# NUC400_v1 register map
File version: 1.0
Registers are 32-bit, read-write, reset 0x0 unless marked. A register's access mark holds for its fields unless they carry their own. Offsets are from the block's base; [hi:lo] are bit positions.

## OTG — OTG Register Map
Base 0x4004D000
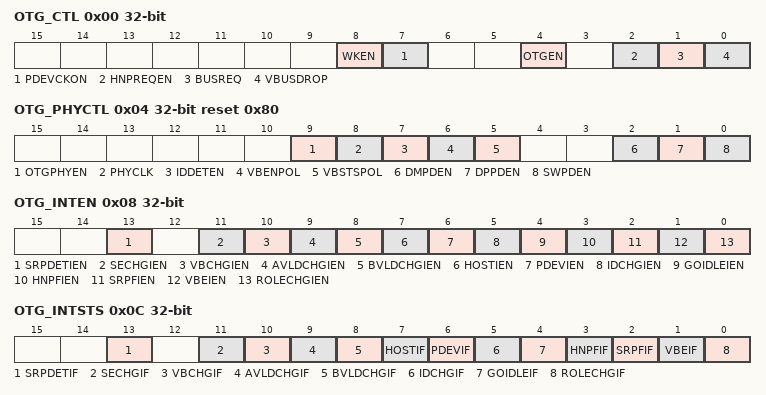
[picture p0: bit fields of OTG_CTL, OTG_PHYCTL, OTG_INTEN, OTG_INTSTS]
0x00 OTG_CTL — OTG Control Register
  [8] WKEN — OTG Wake-Up Enable Bit
    0=OTG ID pin status change wake-up Disabled; 1=OTG ID pin status change wake-up Enabled
  [7] PDEVCKON — Force OTG PHY Output Clock To USB Device. If software configures OTG controller as OTG device and OTG device as A-device, OTG controller will output OTG PHY clock (30 MHz) to USB device only when OTG device as A-peripheral. If software needs to configure USB device before role change (from A-Host to A-Peripheral), software can set this bit high to output OTG PHY clock to USB device.
    0=USB device clock is available only when OTG device as a peripheral; 1=Force output OTG PHY clock to USB device
  [4] OTGEN — OTG Function Enable Bit. If USB is configured as OTG device, this bit must set high.
    0=OTG function Disabled; 1=OTG function Enabled
  [2] HNPREQEN — OTG B-Device HNP Enable/Request. Set this bit to TRUE after the OTG A-device successfully sends a SetFeature(b_hnp_enable) command to the OTG B-device This bit will be cleared automatically when a bus reset or SESS_VLD goes from TRUE to FALSE.
  [1] BUSREQ — OTG A-Device Bus Request. If user application of an OTG A-device wants to do data transfers via USB bus, set this bit to high Otherwise if user application won't use the bus any more, set this bit low. This bit will be automatically cleared if VBUSDROP bit is set to TRUE.
  [0] VBUSDROP — Drop The VUSB Bus. If user application running on this OTG A-device wants to conserve power consumption, set this bit to high When set this bit to TRUE, BUSREQ shall be cleared as well.
    0=Did Not drop the VBUS and keep going on USB data transfers; 1=Drop the VBUS to conserve power consumption
0x04 OTG_PHYCTL reset 0x80 — OTG PHY Control Register
  [9] OTGPHYEN — OTG PHY Enable Control when Device Configured as OTG-Device. When device is configured as OTG-device, hardware will not enable OTG PHY automatically. Software can set OTG_EN to enable OTG PHY.
    0=OTG PHY Disabled; 1=OTG PHY Enabled
  [8] PHYCLK — PHY Input Clock Selection
    0=PHY input clock is12 MHz; 1=PHY input clock is 24 MHz
  [7] IDDETEN — ID Detection Enable
    0=Sampling on ID pin Enabled; 1=Sampling on ID pin Disabled
  [6] VBENPOL — Off-Chip USB VBUS Power Enable Polarity. The OTG controller will enable off-chip USB VBUS LDO to provide VBUS power when need. The polarity of enabling off-chip BSU VBUS LDO (high active or low active) depends on the selected component. This bit provides the inverse option of off-chip USB VBUS LDO enable.
    0=The polarity of enabling off-chip USB VBUS LDO from the OTG controller not inversed; 1=The polarity of enabling off-chip USB VBUS LDO from the OTG controller inversed
  [5] VBSTSPOL — Off-Chip USB VBUS Power Status Polarity. The polarity of off-chip USB VBUS LDO valid depends on the selected component. This bit provides the inversed option of off-chip USB VBUS LDO valid.
    0=The polarity of off-chip USB VBUS LDO valid not inversed; 1=The polarity of off-chip USB VBUS LDO valid inversed
  [2] DMPDEN
    1=15 k resistor pull-down on D- pin Enabled
  [1] DPPDEN
    1=15 k resistor pull-down on D+ pin Enabled
  [0] SWPDEN — Software Control Pull-Down On Data Lines Enable Bit. Note: Software must set this bit high before controlling DPPDEN and DMPDEN.
    0=Pull-down resistors on data lines is controlled by OTG control logic; 1=Pull-down resistors on data lines is controlled by software
0x08 OTG_INTEN — OTG Interrupt Enable Register
  [13] SRPDETIEN — SRP Detected Interrupt Enable Bit
    0=Interrupt Disabled; 1=Interrupt Enabled
  [11] SECHGIEN — SESSEND Status Changed Interrupt Enable Bit
    0=Interrupt Disabled; 1=Interrupt Enabled
  [10] VBCHGIEN — VBVALID Status Changed Interrupt Enable Bit
    0=Interrupt Disabled; 1=Interrupt Enabled
  [9] AVLDCHGIEN — A-Device Session Valid Status Change (From High To Low Or From Low To High) Interrupt Enable Bit
    0=Interrupt Disabled; 1=Interrupt Enabled
  [8] BVLDCHGIEN — B-Device Session Valid Status Change (From High To Low Or From Low To High) Interrupt Enable Bit
    0=Interrupt Disabled; 1=Interrupt Enabled
  [7] HOSTIEN — Act As Host Interrupt Enable Bit
    0=This device as a host interrupt Disabled; 1=This device as a host interrupt Enabled
  [6] PDEVIEN — Act As Peripheral Interrupt Enable Bit
    0=This device as a peripheral interrupt Disabled; 1=This device as a peripheral interrupt Enabled
  [5] IDCHGIEN — IDSTS Changed Interrupt Enable
    0=Interrupt Disabled; 1=Interrupt Enabled
  [4] GOIDLEIEN — OTG Device Goes IDLE State Interrupt Enable Bit. Note: Going to idle state means going to a_idle or b_idle state. Please refer to A-device state diagram and B-device state diagram in OTG spec.
    0=Interrupt Disabled; 1=Interrupt Enabled
  [3] HNPFIEN — HNP Fail Interrupt Enable Bit
    0=Interrupt Disabled; 1=Interrupt Enabled
  [2] SRPFIEN — SRP Fail Interrupt Enable Bit
    0=Interrupt Disabled; 1=Interrupt Enabled
  [1] VBEIEN — VBUS Error Interrupt Enable Bit. Note: VBUS error means going to a_vbus_err state. Please refer to A-device state diagram in OTG spec.
    0=Interrupt Disabled; 1=Interrupt Enabled
  [0] ROLECHGIEN — Role(Host Or Peripheral) Changed Interrupt Enable Bit
    0=Interrupt Disabled; 1=Interrupt Enabled
0x0C OTG_INTSTS — OTG Interrupt Status Register
  [13] SRPDETIF — SRP Detected Interrupt Status. Note: Write 1 to clear this status.
    0=SRP not detected; 1=SRP detected
  [11] SECHGIF — SESSEND State Change Interrupt Status. Note: Write 1 to clear this flag.
    0=Session end not toggled; 1=SESSEND from high to low or from low to high
  [10] VBCHGIF — VBVALID State Change Interrupt Status. Note: Write 1 to clear this flag.
    0=VBUS_VLD not toggled; 1=VBUS_VLD from high to low or from low to high
  [9] AVLDCHGIF — A-Device Session Valid State Change Interrupt Status. Note: Write 1 to clear this flag.
    0=AVLD not toggled; 1=AVLD from high to low or low to high
  [8] BVLDCHGIF — B-Device Session Valid State Change Interrupt Status. Note: Write 1 to clear this status.
    0=BVLD not toggled; 1=BVLD from high to low or low to high
  [7] HOSTIF — Act As Host Interrupt Status. Note: Write 1 to clear this flag.
    0=This device does not act as a host; 1=This device acts as a host
  [6] PDEVIF — Act As Peripheral Interrupt Status. Note: Write 1 to clear this flag.
    0=This device does not act as a peripheral; 1=This device acts as a peripheral
  [5] IDCHGIF — ID State Change Interrupt Status. Note1: BUSREQ (OTG_CTL[1]) will be cleared when IDDIG is high. Note2: Write 1 to clear this flag.
    0=IDSTS not toggled; 1=IDSTS from high to low or from low to high
  [4] GOIDLEIF — OTG Device Goes IDLE Interrupt Status. Flag is set if the OTG device transfers from non-idle state to idle state. The OTG device will be neither a host nor a peripheral. Note: Write 1 to clear this flag.
    0=OTG device does not go back to idle state(a_idle or b_idle); 1=OTG device go back to idle state(a_idle or b_idle)
  [3] HNPFIF — HNP Fail Interrupt Status. When A-device has granted B-device to be host and USB bus in SE0 state, this bit will be set in specified interval (b_ase0_brst_tmr, defined in OTG spec. specification), A-device does not signal connect signal. Note: Write 1 to clear this flag.
  [2] SRPFIF — SRP Fail Interrupt Status. After initiating SRP, an OTG B-device will wait at least TB_SRP_FAIL min, defined in OTG specification, for the OTG A-device respond This flag is set when the OTG B-device didn't get the response from the remote A-device to turn VBUS on and generate a bus reset. Note: Write 1 to clear this flag.
  [1] VBEIF — VBUS Error Interrupt Status. This flag will be set in one of two conditions. One case is that voltage on VBUS cannot reach a minimum valid threshold 4.4V within a maximum time of 100ms after OTG A device starting to drive. The other case is that the supplied VBUS drops below a minimum valid threshold due to the overcurrent condition. Note: Write 1 to clear this flag and recover from the VBUS error state.
  [0] ROLECHGIF — OTG Role Change Interrupt Status. This flag is set when the role of an OTG device changed from a host to a peripheral, or changed from a peripheral to a host. Note: Write 1 to clear this flag.
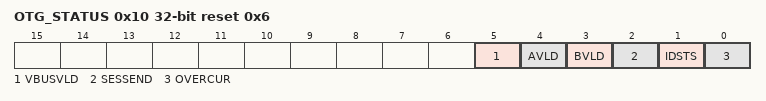
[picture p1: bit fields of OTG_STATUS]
0x10 OTG_STATUS ro reset 0x6 — Functional Status Register
  [5] VBUSVLD — VBUS Valid Status
    0=VBUS 4.4V; 1=VBUS 4.75V
  [4] AVLD — A-Device Session Valid Status
    0=VBUS 0.8V; 1=VBUS 2V
  [3] BVLD — B-Device Session Valid Status
    0=VBUS 0.8V; 1=VBUS 4V
  [2] SESSEND — Session End Status
    0=VBUS 0.8V; 1=VBUS 0.2V
  [1] IDSTS — ID Pin State Of Mini-B/Micro-Plug
    0=Mini-A/Micro-A plug is attached; 1=Mini-B/Micro-B plug is attached
  [0] OVERCUR — Overcurrent Condition. The voltage on VBUS cannot reach a minimum VBUS valid threshold, 4.4V minimum, within a maximum time of 100ms after OTG A device starting to drive
    0=OTG A-device drives VBUS successfully; 1=Overcurrent condition occurred
